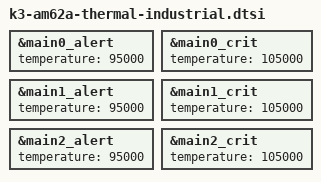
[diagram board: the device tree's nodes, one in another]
// SPDX-License-Identifier: GPL-2.0-only OR MIT
/*
 * Copyright (C) 2025 PHYTEC Messtechnik GmbH
 */

&main0_alert {
	temperature = <95000>;
};

&main0_crit {
	temperature = <105000>;
};

&main1_alert {
	temperature = <95000>;
};

&main1_crit {
	temperature = <105000>;
};

&main2_alert {
	temperature = <95000>;
};

&main2_crit {
	temperature = <105000>;
};
